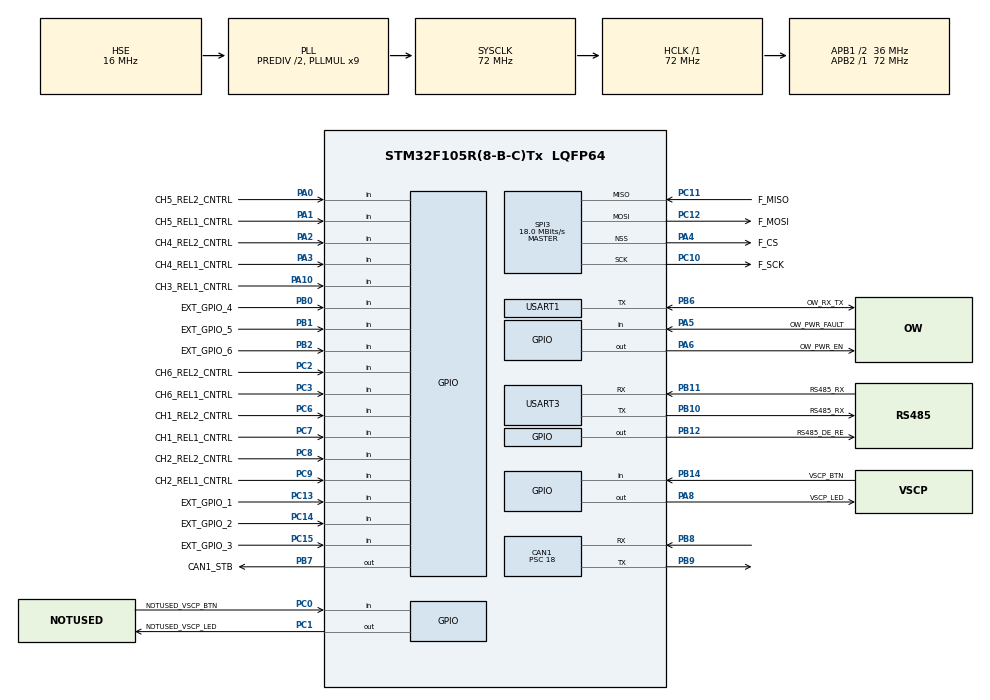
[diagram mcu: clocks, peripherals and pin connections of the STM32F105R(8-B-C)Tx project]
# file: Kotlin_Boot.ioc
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CAN1.ABOM=ENABLE
CAN1.BS1=CAN_BS1_13TQ
CAN1.BS2=CAN_BS2_2TQ
CAN1.CalculateTimeBit=8000
CAN1.CalculateTimeQuantum=500.0
CAN1.Prescaler=18
CAN1.SJW=CAN_SJW_4TQ
Mcu.Family=STM32F1
Mcu.Name=STM32F105R(8-B-C)Tx
Mcu.Package=LQFP64
Mcu.UserConstants=VSCP_CORE_PERIOD,100;VSCP_TIMER_PERIOD,1000;VSCP_LED_PERIOD_FAST,100;VSCP_LED_PERIOD_SLOW,800;VSCP_CAN_TX_TIMEOUT_MS,10
NVIC.CAN1_RX0_IRQn=true\:0\:0\:false\:false\:true\:true
NVIC.CAN1_TX_IRQn=true\:0\:0\:false\:false\:true\:true
NVIC.PriorityGroup=NVIC_PRIORITYGROUP_4
NVIC.TIM7_IRQn=true\:0\:0\:false\:false\:true\:false
NVIC.TimeBase=TIM7_IRQn
NVIC.TimeBaseIP=TIM7
PA0-WKUP.GPIO_Label=CH5_REL2_CNTRL
PA0-WKUP.Signal=GPIO_Input
PA1.GPIO_Label=CH5_REL1_CNTRL
PA1.Signal=GPIO_Input
PA10.GPIO_Label=CH3_REL1_CNTRL
PA10.Signal=GPIO_Input
PA11.Signal=USB_OTG_FS_DM
PA12.Signal=USB_OTG_FS_DP
PA13.Mode=Trace_Asynchronous_SW
PA13.Signal=SYS_JTMS-SWDIO
PA14.Mode=Trace_Asynchronous_SW
PA14.Signal=SYS_JTCK-SWCLK
PA2.GPIO_Label=CH4_REL2_CNTRL
PA2.Signal=GPIO_Input
PA3.GPIO_Label=CH4_REL1_CNTRL
PA3.Signal=GPIO_Input
PA4.GPIO_Label=F_CS
PA4.Mode=NSS_Signal_Hard_Output
PA4.Signal=SPI3_NSS
PA5.GPIO_Label=OW_PWR_FAULT
PA5.Signal=GPIO_Input
PA6.GPIO_Label=OW_PWR_EN
PA6.Signal=GPIO_Output
PA8.GPIO_Label=VSCP_LED
PA8.Signal=GPIO_Output
PA9.Signal=USB_OTG_FS_VBUS
PB0.GPIO_Label=EXT_GPIO_4
PB0.GPIO_PuPd=GPIO_PULLDOWN
PB0.Signal=GPIO_Input
PB1.GPIO_Label=EXT_GPIO_5
PB1.GPIO_PuPd=GPIO_PULLDOWN
PB1.Signal=GPIO_Input
PB10.GPIO_Label=RS485_RX
PB10.Mode=Asynchronous
PB10.Signal=USART3_TX
PB11.GPIO_Label=RS485_RX
PB11.Mode=Asynchronous
PB11.Signal=USART3_RX
PB12.GPIO_Label=RS485_DE_RE
PB12.Signal=GPIO_Output
PB13.GPIO_Label=EXT_SPI_SCK
PB13.Signal=SPI2_SCK
PB14.GPIO_Label=VSCP_BTN
PB14.Signal=GPIO_Input
PB15.GPIO_Label=EXT_SPI_MOSI
PB15.Signal=SPI2_MOSI
PB2.GPIO_Label=EXT_GPIO_6
PB2.GPIO_PuPd=GPIO_PULLDOWN
PB2.Signal=GPIO_Input
PB3.Mode=Trace_Asynchronous_SW
PB3.Signal=SYS_TRACESWO
PB6.GPIO_Label=OW_RX_TX
PB6.Mode=Half_duplex(single_wire_mode)
PB6.Signal=USART1_TX
PB7.GPIO_Label=CAN1_STB
PB7.GPIO_ModeDefaultOutputPP=GPIO_MODE_OUTPUT_PP
PB7.GPIO_Speed=GPIO_SPEED_FREQ_LOW
PB7.PinState=GPIO_PIN_SET
PB7.Signal=GPIO_Output
PB8.Mode=Master
PB8.Signal=CAN1_RX
PB9.Mode=Master
PB9.Signal=CAN1_TX
PC0.GPIO_Label=NOTUSED_VSCP_BTN
PC0.Signal=GPIO_Input
PC1.GPIO_Label=NOTUSED_VSCP_LED
PC1.Signal=GPIO_Output
PC10.GPIO_Label=F_SCK
PC10.Mode=Full_Duplex_Master
PC10.Signal=SPI3_SCK
PC11.GPIO_Label=F_MISO
PC11.Mode=Full_Duplex_Master
PC11.Signal=SPI3_MISO
PC12.GPIO_Label=F_MOSI
PC12.Mode=Full_Duplex_Master
PC12.Signal=SPI3_MOSI
PC13-TAMPER-RTC.GPIO_Label=EXT_GPIO_1
PC13-TAMPER-RTC.Signal=GPIO_Input
PC14-OSC32_IN.GPIO_Label=EXT_GPIO_2
PC14-OSC32_IN.Signal=GPIO_Input
PC15-OSC32_OUT.GPIO_Label=EXT_GPIO_3
PC15-OSC32_OUT.Signal=GPIO_Input
PC2.GPIO_Label=CH6_REL2_CNTRL
PC2.Signal=SharedStack_PC2
PC2.Stacked=true
PC3.GPIO_Label=CH6_REL1_CNTRL
PC3.Signal=GPIO_Input
PC6.GPIO_Label=CH1_REL2_CNTRL
PC6.Signal=GPIO_Input
PC7.GPIO_Label=CH1_REL1_CNTRL
PC7.Signal=GPIO_Input
PC8.GPIO_Label=CH2_REL2_CNTRL
PC8.Signal=GPIO_Input
PC9.GPIO_Label=CH2_REL1_CNTRL
PC9.Signal=GPIO_Input
PD0-OSC_IN.Mode=HSE-External-Oscillator
PD0-OSC_IN.Signal=RCC_OSC_IN
PD1-OSC_OUT.Mode=HSE-External-Oscillator
PD1-OSC_OUT.Signal=RCC_OSC_OUT
ProjectManager.HeapSize=0x400
ProjectManager.StackSize=0x200
ProjectManager.TargetToolchain=MDK-ARM V5
RCC.AHBFreq_Value=72000000
RCC.APB1CLKDivider=RCC_HCLK_DIV2
RCC.APB1Freq_Value=36000000
RCC.APB1TimFreq_Value=72000000
RCC.APB2Freq_Value=72000000
RCC.APB2TimFreq_Value=72000000
RCC.HCLKFreq_Value=72000000
RCC.HSEDivPLL=RCC_HSE_PREDIV_DIV2
RCC.HSE_VALUE=16000000
RCC.PLLMUL=RCC_PLL_MUL9
RCC.PLLSourceVirtual=RCC_PLLSOURCE_HSE
RCC.SYSCLKFreq_VALUE=72000000
RCC.SYSCLKSource=RCC_SYSCLKSOURCE_PLLCLK
RCC.USBFreq_Value=48000000
SH.SharedStack_PC2.0=GPIO_Input
SPI3.CalculateBaudRate=18.0 MBits/s
SPI3.Direction=SPI_DIRECTION_2LINES
SPI3.Mode=SPI_MODE_MASTER
SPI3.VirtualNSS=VM_NSSHARD
SPI3.VirtualType=VM_MASTER
USART1.VirtualMode=VM_ASYNC
USART3.VirtualMode=VM_ASYNC
VP_SYS_VS_tim7.Mode=TIM7
board=Kotlin_Boot

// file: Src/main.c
/**
  ******************************************************************************
  * File Name          : main.c
  * Description        : Main program body
  ******************************************************************************
  ** This notice applies to any and all portions of this file
  * that are not between comment pairs USER CODE BEGIN and
  * USER CODE END. Other portions of this file, whether
  * inserted by the user or by software development tools
  * are owned by their respective copyright owners.
  *
  * COPYRIGHT(c) 2018 STMicroelectronics
  *
  * Redistribution and use in source and binary forms, with or without modification,
  * are permitted provided that the following conditions are met:
  *   1. Redistributions of source code must retain the above copyright notice,
  *      this list of conditions and the following disclaimer.
  *   2. Redistributions in binary form must reproduce the above copyright notice,
  *      this list of conditions and the following disclaimer in the documentation
  *      and/or other materials provided with the distribution.
  *   3. Neither the name of STMicroelectronics nor the names of its contributors
  *      may be used to endorse or promote products derived from this software
  *      without specific prior written permission.
  *
  * THIS SOFTWARE IS PROVIDED BY THE COPYRIGHT HOLDERS AND CONTRIBUTORS "AS IS"
  * AND ANY EXPRESS OR IMPLIED WARRANTIES, INCLUDING, BUT NOT LIMITED TO, THE
  * IMPLIED WARRANTIES OF MERCHANTABILITY AND FITNESS FOR A PARTICULAR PURPOSE ARE
  * DISCLAIMED. IN NO EVENT SHALL THE COPYRIGHT HOLDER OR CONTRIBUTORS BE LIABLE
  * FOR ANY DIRECT, INDIRECT, INCIDENTAL, SPECIAL, EXEMPLARY, OR CONSEQUENTIAL
  * DAMAGES (INCLUDING, BUT NOT LIMITED TO, PROCUREMENT OF SUBSTITUTE GOODS OR
  * SERVICES; LOSS OF USE, DATA, OR PROFITS; OR BUSINESS INTERRUPTION) HOWEVER
  * CAUSED AND ON ANY THEORY OF LIABILITY, WHETHER IN CONTRACT, STRICT LIABILITY,
  * OR TORT (INCLUDING NEGLIGENCE OR OTHERWISE) ARISING IN ANY WAY OUT OF THE USE
  * OF THIS SOFTWARE, EVEN IF ADVISED OF THE POSSIBILITY OF SUCH DAMAGE.
  *
  ******************************************************************************
  */

#include "main.h"
#include "stm32f1xx_hal.h"
#include "can.h"
#include "spi.h"
#include "usart.h"
#include "gpio.h"

/* USER CODE BEGIN Includes */
#include "eeprom.h"
#include "vscp_bootloader.h"
/* USER CODE END Includes */

/* USER CODE BEGIN PV */
/* Private variables ---------------------------------------------------------*/

/* USER CODE END PV */

void SystemClock_Config(void);

/* USER CODE BEGIN PFP */
/* Private function prototypes -----------------------------------------------*/

/* USER CODE END PFP */

/* USER CODE BEGIN 0 */
int fputc(int c, FILE *stream)
{
   return(ITM_SendChar(c));
}
/* USER CODE END 0 */

int main(void)
{

  /* MCU Configuration----------------------------------------------------------*/

  /* Reset of all peripherals, Initializes the Flash interface and the Systick. */
  HAL_Init();

  /* Configure the system clock */
  SystemClock_Config();

  /* Initialize all configured peripherals */
  MX_GPIO_Init();
  MX_CAN1_Init();
  MX_SPI3_Init();
  MX_USART3_UART_Init();
  MX_USART1_UART_Init();

  /* USER CODE BEGIN 2 */
  HAL_FLASH_Unlock();

  /* USER CODE END 2 */
  vscp_bootloader_init();
  vscp_bootloader_run();
  /* Infinite loop */
  while (1)
  {

  }

}

/** System Clock Configuration
*/
void SystemClock_Config(void)
{

  RCC_OscInitTypeDef RCC_OscInitStruct;
  RCC_ClkInitTypeDef RCC_ClkInitStruct;

    /**Initializes the CPU, AHB and APB busses clocks
    */
  RCC_OscInitStruct.OscillatorType = RCC_OSCILLATORTYPE_HSE;
  RCC_OscInitStruct.HSEState = RCC_HSE_ON;
  RCC_OscInitStruct.HSEPredivValue = RCC_HSE_PREDIV_DIV2;
  RCC_OscInitStruct.HSIState = RCC_HSI_ON;
  RCC_OscInitStruct.Prediv1Source = RCC_PREDIV1_SOURCE_HSE;
  RCC_OscInitStruct.PLL.PLLState = RCC_PLL_ON;
  RCC_OscInitStruct.PLL.PLLSource = RCC_PLLSOURCE_HSE;
  RCC_OscInitStruct.PLL.PLLMUL = RCC_PLL_MUL9;
  RCC_OscInitStruct.PLL2.PLL2State = RCC_PLL_NONE;
  if (HAL_RCC_OscConfig(&RCC_OscInitStruct) != HAL_OK)
  {
    _Error_Handler(__FILE__, __LINE__);
  }

    /**Initializes the CPU, AHB and APB busses clocks
    */
  RCC_ClkInitStruct.ClockType = RCC_CLOCKTYPE_HCLK|RCC_CLOCKTYPE_SYSCLK
                              |RCC_CLOCKTYPE_PCLK1|RCC_CLOCKTYPE_PCLK2;
  RCC_ClkInitStruct.SYSCLKSource = RCC_SYSCLKSOURCE_PLLCLK;
  RCC_ClkInitStruct.AHBCLKDivider = RCC_SYSCLK_DIV1;
  RCC_ClkInitStruct.APB1CLKDivider = RCC_HCLK_DIV2;
  RCC_ClkInitStruct.APB2CLKDivider = RCC_HCLK_DIV1;

  if (HAL_RCC_ClockConfig(&RCC_ClkInitStruct, FLASH_LATENCY_2) != HAL_OK)
  {
    _Error_Handler(__FILE__, __LINE__);
  }

    /**Configure the Systick interrupt time
    */
  HAL_SYSTICK_Config(HAL_RCC_GetHCLKFreq()/1000);

    /**Configure the Systick
    */
  HAL_SYSTICK_CLKSourceConfig(SYSTICK_CLKSOURCE_HCLK);

    /**Configure the Systick interrupt time
    */
  __HAL_RCC_PLLI2S_ENABLE();

  /* SysTick_IRQn interrupt configuration */
  HAL_NVIC_SetPriority(SysTick_IRQn, 0, 0);
}

void HAL_TIM_PeriodElapsedCallback(TIM_HandleTypeDef *htim)
{
  if (htim->Instance == TIM7) {
    HAL_IncTick();
  }
}

void _Error_Handler(char * file, int line)
{
  while(1)
  {
  }
}

/************************ (C) COPYRIGHT STMicroelectronics *****END OF FILE****/
